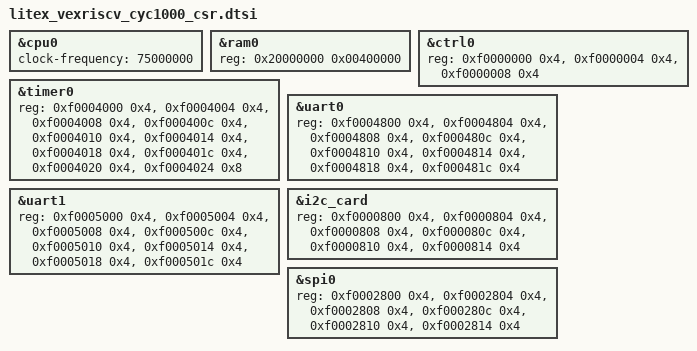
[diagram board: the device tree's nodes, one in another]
/*
 * AUTO-GENERATED — DO NOT EDIT.
 * Target:  litex_vexriscv_cyc1000
 * Source:  /home/wolff/AES67/litex_soc/build/cyc1000/csr.json
 * Regenerate by re-running `make` in litex_soc/ and rebuilding the app.
 */

&cpu0 {
	clock-frequency = <75000000>;
};

&ram0 {
	reg = <0x20000000 0x00400000>;
};

&ctrl0 {
	reg = <0xf0000000 0x4>,
	      <0xf0000004 0x4>,
	      <0xf0000008 0x4>;
};

&timer0 {
	reg = <0xf0004000 0x4>,
	      <0xf0004004 0x4>,
	      <0xf0004008 0x4>,
	      <0xf000400c 0x4>,
	      <0xf0004010 0x4>,
	      <0xf0004014 0x4>,
	      <0xf0004018 0x4>,
	      <0xf000401c 0x4>,
	      <0xf0004020 0x4>,
	      <0xf0004024 0x8>;
};

&uart0 {
	reg = <0xf0004800 0x4>,
	      <0xf0004804 0x4>,
	      <0xf0004808 0x4>,
	      <0xf000480c 0x4>,
	      <0xf0004810 0x4>,
	      <0xf0004814 0x4>,
	      <0xf0004818 0x4>,
	      <0xf000481c 0x4>;
};

&uart1 {
	reg = <0xf0005000 0x4>,
	      <0xf0005004 0x4>,
	      <0xf0005008 0x4>,
	      <0xf000500c 0x4>,
	      <0xf0005010 0x4>,
	      <0xf0005014 0x4>,
	      <0xf0005018 0x4>,
	      <0xf000501c 0x4>;
};

&i2c_card {
	reg = <0xf0000800 0x4>,
	      <0xf0000804 0x4>,
	      <0xf0000808 0x4>,
	      <0xf000080c 0x4>,
	      <0xf0000810 0x4>,
	      <0xf0000814 0x4>;
};

&spi0 {
	reg = <0xf0002800 0x4>,
	      <0xf0002804 0x4>,
	      <0xf0002808 0x4>,
	      <0xf000280c 0x4>,
	      <0xf0002810 0x4>,
	      <0xf0002814 0x4>;
};

